# STMP3770 register map
Vendor: Freescale Semiconductor (NXP); Series: STMP37xx; File version: 1.0
CPU: other r0p0, little endian, no MPU, no FPU, 2 interrupt priority bits
Registers are 32-bit, read-write, reset 0x0 unless marked. A register's access mark holds for its fields unless they carry their own. Offsets are from the block's base; [hi:lo] are bit positions; {n}, {i} and the like mark numbered series; 'fields as' and 'values as' point back to an identical list.

## LRADC — STMP3770 LRADC 外设寄存器与位域中文描述
Base 0x80050000
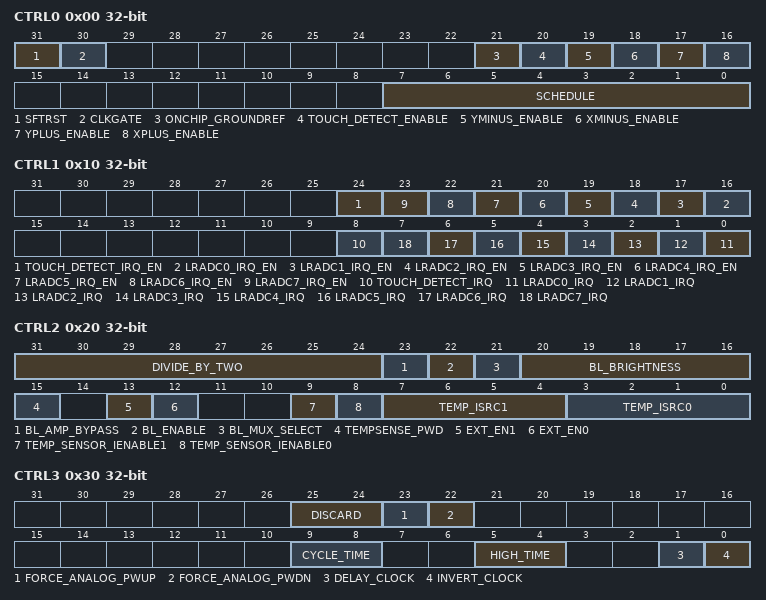
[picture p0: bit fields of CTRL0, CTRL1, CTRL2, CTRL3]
0x00 CTRL0 — LRADC 控制寄存器 0，负责通道调度、触摸屏电极使能、片内地参考及模块级时钟/复位控制。
  [31] SFTRST — 软复位控制，置位时对 LRADC 模块执行软件复位。
  [30] CLKGATE — 时钟门控控制，置位时关闭 LRADC 模块时钟以节省功耗。
  [21] ONCHIP_GROUNDREF — 片内地参考使能，ON 时使用芯片内部地作为 ADC 参考地。
    0=OFF; 1=ON
  [20] TOUCH_DETECT_ENABLE — 触摸检测功能使能，ON 时启用面板触摸按下/释放检测逻辑。
    0=OFF; 1=ON
  [19] YMINUS_ENABLE — 触摸屏 Y- 电极驱动使能，ON 时接通 Y- 面板电极用于坐标采样。
    0=OFF; 1=ON
  [18] XMINUS_ENABLE — 触摸屏 X- 电极驱动使能，ON 时接通 X- 面板电极用于坐标采样。
    0=OFF; 1=ON
  [17] YPLUS_ENABLE — 触摸屏 Y+ 电极驱动使能，ON 时接通 Y+ 面板电极用于坐标采样。
    0=OFF; 1=ON
  [16] XPLUS_ENABLE — 触摸屏 X+ 电极驱动使能，ON 时接通 X+ 面板电极用于坐标采样。
    0=OFF; 1=ON
  [7:0] SCHEDULE — 8 位按位调度掩码，置位对应位即启动 LRADC 通道 0~7 的 ADC 转换。
0x10 CTRL1 — LRADC 控制寄存器 1，管理各通道转换完成中断状态及对应中断使能。
  [24] TOUCH_DETECT_IRQ_EN — 触摸检测中断使能，ENABLE 时允许触摸检测事件产生中断。
    0=DISABLE; 1=ENABLE
  [n+16] LRADC{n}_IRQ_EN (n=0..7) — LRADC 通道 {n} 转换完成中断使能，ENABLE 时允许该通道转换结束后产生中断。
    0=DISABLE; 1=ENABLE
  [8] TOUCH_DETECT_IRQ — 触摸检测中断状态，PENDING 表示检测到触摸事件，写 CLEAR 清除。
    0=CLEAR; 1=PENDING
  [n] LRADC{n}_IRQ (n=0..7) — LRADC 通道 {n} 转换完成中断状态，PENDING 表示中断挂起，写 CLEAR 清除。
    0=CLEAR; 1=PENDING
0x20 CTRL2 — LRADC 控制寄存器 2，配置温度传感器电流源、背光控制及各通道输入分频。
  [31:24] DIVIDE_BY_TWO — 各通道输入二分频使能掩码，8 位按位控制通道 0~7 的输入是否先经 1/2 分压再进入 ADC。
  [23] BL_AMP_BYPASS — 背光放大器旁路使能，ENABLE 时绕过背光放大器直接输出。
    0=DISABLE; 1=ENABLE
  [22] BL_ENABLE — 背光模块使能，置位时打开背光驱动电路。
  [21] BL_MUX_SELECT — 背光多路选择器控制，用于选择背光驱动信号的输入源。
  [20:16] BL_BRIGHTNESS — 背光亮度等级设置，5 位数值用于控制背光 PWM 或 DAC 亮度输出。
  [15] TEMPSENSE_PWD — 温度传感器掉电控制，ENABLE 时关闭温感电路以节省功耗。
    0=DISABLE; 1=ENABLE
  [13] EXT_EN1 — 外部扩展使能 1，控制外部模拟通路或扩展通道的开关。
    0=DISABLE; 1=ENABLE
  [12] EXT_EN0 — 外部扩展使能 0，控制外部模拟通路或扩展通道的开关。
  [9] TEMP_SENSOR_IENABLE1 — 温度传感器 1 电流源使能，ENABLE 时打开 TEMP1 的恒流源供电。
    0=DISABLE; 1=ENABLE
  [8] TEMP_SENSOR_IENABLE0 — 温度传感器 0 电流源使能，ENABLE 时打开 TEMP0 的恒流源供电。
    0=DISABLE; 1=ENABLE
  [7:4] TEMP_ISRC1 — 温度传感器 1 电流源强度选择，枚举值从 300μA 递减至 0μA，用于温感二极管偏置。
    15=_300; 14=_280; 13=_260; 12=_240; 11=_220; 10=_200; 9=_180; 8=_160; 7=_140; 6=_120; 5=_100; 4=_80; 3=_60; 2=_40; 1=_20; 0=ZERO
  [3:0] TEMP_ISRC0 — 温度传感器 0 电流源强度选择，枚举值从 300μA 递减至 0μA，用于温感二极管偏置。
    values as TEMP_ISRC1
0x30 CTRL3 — LRADC 控制寄存器 3，配置 ADC 采样时钟相位、采样高电平时间、转换周期、模拟电源强制状态及初始丢弃样本数。
  [25:24] DISCARD — 初始丢弃样本数选择，启动后自动丢弃前 1/2/3 个样本以稳定 ADC 结果。
    1=_1_SAMPLE; 2=_2_SAMPLES; 3=_3_SAMPLES
  [23] FORCE_ANALOG_PWUP — 强制模拟电路上电控制，ON 时强制开启模拟部分电源。
    0=OFF; 1=ON
  [22] FORCE_ANALOG_PWDN — 强制模拟电路掉电控制，ON 时强制关闭模拟部分电源。
    0=ON; 1=OFF
  [9:8] CYCLE_TIME — ADC 转换周期时间选择，决定采样速率对应的时钟频率(6/4/3/2 MHz)。
    0=_6MHZ; 1=_4MHZ; 2=_3MHZ; 3=_2MHZ
  [5:4] HIGH_TIME — ADC 采样高电平保持时间选择，决定采样开关导通时长(42/83/125/250 ns)。
    0=_42NS; 1=_83NS; 2=_125NS; 3=_250NS
  [1] DELAY_CLOCK — ADC 采样时钟延迟控制，DELAYED 时引入额外时钟延迟以调整采样相位。
    0=NORMAL; 1=DELAYED
  [0] INVERT_CLOCK — ADC 采样时钟相位反转控制，INVERT 时翻转采样时钟极性。
    0=NORMAL; 1=INVERT
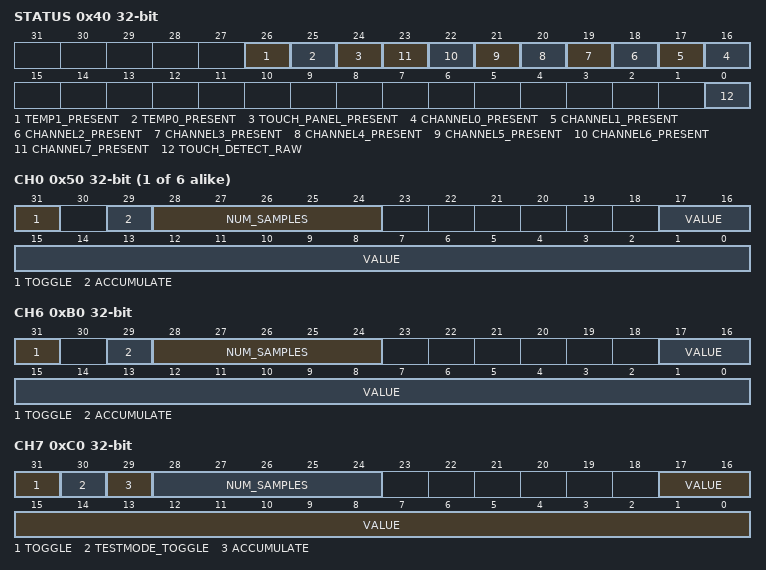
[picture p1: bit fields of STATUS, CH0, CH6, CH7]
0x40 STATUS ro — LRADC 状态寄存器，反映触摸检测原始状态、各通道及外设的存在性标志。
  [26] TEMP1_PRESENT — 温度传感器 1 存在性标志，置位表示 TEMP1 通道可用。
  [25] TEMP0_PRESENT — 温度传感器 0 存在性标志，置位表示 TEMP0 通道可用。
  [24] TOUCH_PANEL_PRESENT — 触摸屏面板存在性标志，置位表示触摸面板已连接。
  [n+16] CHANNEL{n}_PRESENT (n=0..7) — 通道 {n} 存在性标志，置位表示该物理通道可用。
  [0] TOUCH_DETECT_RAW — 触摸检测原始状态，OPEN 表示未触摸，HIT 表示面板被触摸。
    0=OPEN; 1=HIT
{0x50+0x10*i} CH{i} (i=0..5) — LRADC 通道结果寄存器(数组 CH0~CH5)，存储 ADC 转换结果并控制累加模式。
  [31] TOGGLE — 通道结果翻转标志，硬件在每次更新结果时自动翻转，软件可用于判断新数据是否就绪。
  [29] ACCUMULATE — 累加使能，置位时启用多次采样累加模式以提高分辨率/抑制噪声。
  [28:24] NUM_SAMPLES — 累加样本数配置，指定一次累加转换中需采样的次数(0~31 对应 1~32 次)。
  [17:0] VALUE — 18 位 ADC 转换结果值，存放该通道最近一次或累加后的采样数据。
0xB0 CH6 — LRADC 通道 6 结果寄存器(VddIO)，存储 VddIO 电压采样结果并支持累加模式。
  [31] TOGGLE — 通道结果翻转标志，硬件在每次更新结果时自动翻转，软件可用于判断新数据是否就绪。
  [29] ACCUMULATE — 累加使能，置位时启用多次采样累加模式以提高分辨率/抑制噪声。
  [28:24] NUM_SAMPLES — 累加样本数配置，指定一次累加转换中需采样的次数。
  [17:0] VALUE — 18 位 ADC 转换结果值，存放 VddIO 通道最近一次或累加后的采样数据。
0xC0 CH7 — LRADC 通道 7 结果寄存器(BATT)，存储电池电压采样结果并支持累加与测试模式。
  [31] TOGGLE — 通道结果翻转标志，硬件在每次更新结果时自动翻转，软件可用于判断新数据是否就绪。
  [30] TESTMODE_TOGGLE — 测试模式翻转控制，用于调试时手动翻转通道 7 的测试状态位。
  [29] ACCUMULATE — 累加使能，置位时启用多次采样累加模式以提高分辨率/抑制噪声。
  [28:24] NUM_SAMPLES — 累加样本数配置，指定一次累加转换中需采样的次数。
  [17:0] VALUE — 18 位 ADC 转换结果值，存放电池通道最近一次或累加后的采样数据。
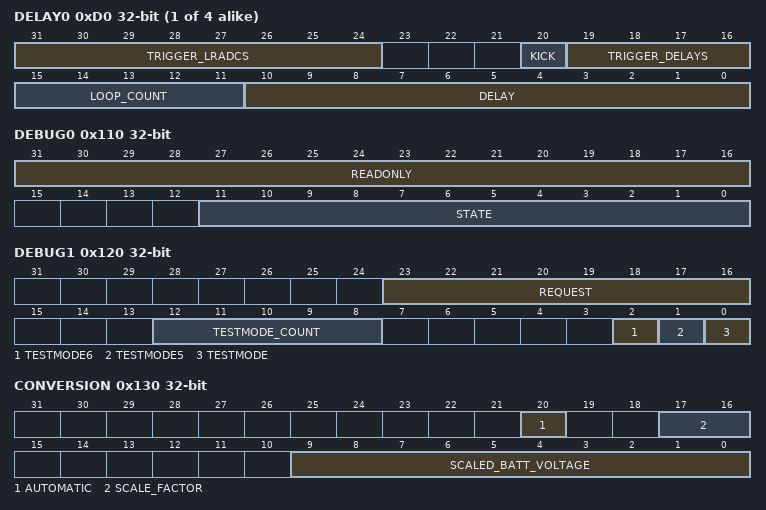
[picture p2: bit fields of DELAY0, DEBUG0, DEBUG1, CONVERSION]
{0xD0+0x10*i} DELAY{i} (i=0..3) — LRADC 延迟触发寄存器(数组 DELAY0~DELAY3)，配置定时延迟、循环计数及触发链。
  [31:24] TRIGGER_LRADCS — LRADC 通道触发掩码，8 位按位选择该延迟到期后触发哪些 LRADC 通道开始转换。
  [20] KICK — 延迟启动触发位，写 1 立即启动该延迟槽的计数器。
  [19:16] TRIGGER_DELAYS — 延迟链触发掩码，4 位按位选择该延迟到期后触发哪些其他 DELAY 槽。
  [15:11] LOOP_COUNT — 循环次数配置，指定该延迟序列需重复执行的次数。
  [10:0] DELAY — 延迟计数值，指定该延迟槽的定时长度，用于控制采样触发的时间间隔。
0x110 DEBUG0 ro — LRADC 调试寄存器 0，提供状态机状态及只读调试信息。
  [31:16] READONLY — 只读调试数据，16 位硬件内部调试信号供分析使用。
  [11:0] STATE — LRADC 内部状态机当前状态值，12 位用于调试跟踪控制器运行阶段。
0x120 DEBUG1 ro — LRADC 调试寄存器 1，提供测试模式控制、测试计数及请求信号调试。
  [23:16] REQUEST — 8 位请求调试信号，反映内部各通道的转换请求状态。
  [12:8] TESTMODE_COUNT — 测试模式计数配置，指定测试序列的计数长度。
  [2] TESTMODE6 — 测试模式 6 控制，TEST 时启用通道 6 相关测试逻辑。
    0=NORMAL; 1=TEST
  [1] TESTMODE5 — 测试模式 5 控制，TEST 时启用通道 5 相关测试逻辑。
    0=NORMAL; 1=TEST
  [0] TESTMODE — 测试模式总开关，TEST 时启用 LRADC 整体测试模式。
    0=NORMAL; 1=TEST
0x130 CONVERSION ro — LRADC 电池转换寄存器，配置电池类型缩放系数及自动转换使能。
  [20] AUTOMATIC — 电池自动转换使能，ENABLE 时启用硬件自动电池电压采样与转换。
    0=DISABLE; 1=ENABLE
  [17:16] SCALE_FACTOR — 电池类型缩放系数选择，决定电池电压到 ADC 量程的映射关系(NiMH/双 NiMH/Li-Ion/替代 Li-Ion)。
    0=NIMH; 1=DUAL_NIMH; 2=LI_ION; 3=ALT_LI_ION
  [9:0] SCALED_BATT_VOLTAGE — 10 位电池电压缩放后值，反映经 SCALE_FACTOR 缩放后的电池电压读数。
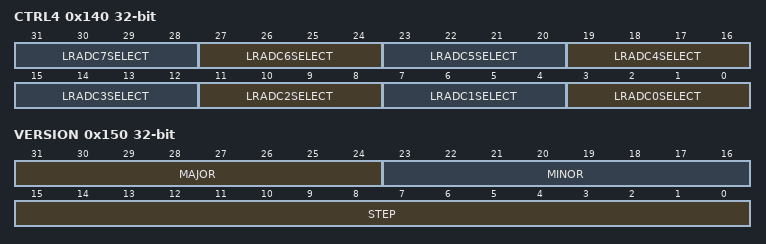
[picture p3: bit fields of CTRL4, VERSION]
0x140 CTRL4 — LRADC 控制寄存器 4，为 8 个虚拟 LRADC 槽分别选择物理输入通道 0~15。
  [all] fields
    {v}=CHANNEL{v} (v=0..15)
  [4n+3:4n] LRADC{n}SELECT (n=0..7) — LRADC 槽 {n} 物理通道选择，4 位编码从 16 路输入通道中选定通道 0~15。
0x150 VERSION ro — LRADC 版本寄存器，记录 IP 核的主版本、次版本及步进号。
  [31:24] MAJOR — 8 位主版本号，标识当前 IP 核的主要版本。
  [23:16] MINOR — 8 位次版本号，标识当前 IP 核的次要版本。
  [15:0] STEP — 16 位步进版本号，标识当前 IP 核的修订步进。
